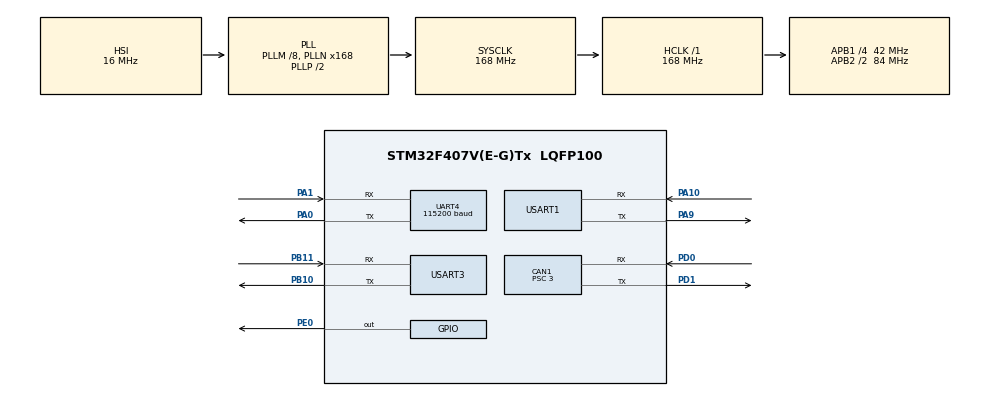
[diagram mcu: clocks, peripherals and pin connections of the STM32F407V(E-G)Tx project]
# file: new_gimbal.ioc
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CAN1.BS1=CAN_BS1_10TQ
CAN1.BS2=CAN_BS2_3TQ
CAN1.CalculateBaudRate=1000000
CAN1.CalculateTimeBit=999.99
CAN1.CalculateTimeQuantum=71.42857142857143
CAN1.Prescaler=3
FREERTOS.Tasks01=defaultTask,0,128,StartDefaultTask,Default,NULL,Dynamic,NULL,NULL;usart_,0,128,usart_task,As external,NULL,Dynamic,NULL,NULL;can_,0,128,can_task,As external,NULL,Dynamic,NULL,NULL
Mcu.Family=STM32F4
Mcu.Name=STM32F407V(E-G)Tx
Mcu.Package=LQFP100
NVIC.CAN1_RX0_IRQn=true\:5\:0\:false\:false\:true\:true\:true\:true
NVIC.PriorityGroup=NVIC_PRIORITYGROUP_4
NVIC.TIM1_UP_TIM10_IRQn=true\:0\:0\:false\:false\:true\:false\:false\:true
NVIC.TimeBase=TIM1_UP_TIM10_IRQn
NVIC.TimeBaseIP=TIM1
NVIC.UART4_IRQn=true\:5\:0\:false\:false\:false\:true\:true\:true
NVIC.USART1_IRQn=true\:5\:0\:false\:false\:true\:true\:true\:true
NVIC.USART3_IRQn=true\:5\:0\:false\:false\:false\:true\:true\:true
PA0-WKUP.Mode=Asynchronous
PA0-WKUP.Signal=UART4_TX
PA1.Mode=Asynchronous
PA1.Signal=UART4_RX
PA10.Mode=Asynchronous
PA10.Signal=USART1_RX
PA13.Mode=Serial_Wire
PA13.Signal=SYS_JTMS-SWDIO
PA14.Mode=Serial_Wire
PA14.Signal=SYS_JTCK-SWCLK
PA9.Mode=Asynchronous
PA9.Signal=USART1_TX
PB10.Mode=Asynchronous
PB10.Signal=USART3_TX
PB11.Mode=Asynchronous
PB11.Signal=USART3_RX
PD0.Mode=CAN_Activate
PD0.Signal=CAN1_RX
PD1.Mode=CAN_Activate
PD1.Signal=CAN1_TX
PE0.Signal=GPIO_Output
PH0-OSC_IN.Mode=HSE-External-Oscillator
PH0-OSC_IN.Signal=RCC_OSC_IN
PH1-OSC_OUT.Mode=HSE-External-Oscillator
PH1-OSC_OUT.Signal=RCC_OSC_OUT
ProjectManager.HeapSize=0x200
ProjectManager.StackSize=0x400
ProjectManager.TargetToolchain=MDK-ARM V5.27
RCC.48MHZClocksFreq_Value=84000000
RCC.AHBFreq_Value=168000000
RCC.APB1CLKDivider=RCC_HCLK_DIV4
RCC.APB1Freq_Value=42000000
RCC.APB1TimFreq_Value=84000000
RCC.APB2CLKDivider=RCC_HCLK_DIV2
RCC.APB2Freq_Value=84000000
RCC.APB2TimFreq_Value=168000000
RCC.CortexFreq_Value=168000000
RCC.HCLKFreq_Value=168000000
RCC.HSE_VALUE=12000000
RCC.HSI_VALUE=16000000
RCC.LSE_VALUE=32768
RCC.PLLM=8
RCC.PLLN=168
RCC.SYSCLKFreq_VALUE=168000000
RCC.SYSCLKSource=RCC_SYSCLKSOURCE_PLLCLK
RCC.VCOOutputFreq_Value=336000000
UART4.BaudRate=115200
UART4.VirtualMode=Asynchronous
USART1.VirtualMode=VM_ASYNC
USART3.VirtualMode=VM_ASYNC
VP_FREERTOS_VS_CMSIS_V1.Mode=CMSIS_V1
VP_SYS_VS_tim1.Mode=TIM1
board=custom

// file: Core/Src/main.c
/* USER CODE BEGIN Header */
/**
  ******************************************************************************
  * @file           : main.c
  * @brief          : Main program body
  ******************************************************************************
  * @attention
  *
  * <h2><center>&copy; Copyright (c) 2021 STMicroelectronics.
  * All rights reserved.</center></h2>
  *
  * This software component is licensed by ST under Ultimate Liberty license
  * SLA0044, the "License"; You may not use this file except in compliance with
  * the License. You may obtain a copy of the License at:
  *                             www.st.com/SLA0044
  *
  ******************************************************************************
  */
/* USER CODE END Header */
#include "main.h"
#include "cmsis_os.h"
#include "can.h"
#include "usart.h"
#include "gpio.h"

void SystemClock_Config(void);
void MX_FREERTOS_Init(void);

/* USER CODE BEGIN 0 */
extern uint8_t RxData[100];
uint8_t config_cmd[5]={0xff,0xaa,0x03,0x0c,0x00};
/* USER CODE END 0 */

int main(void)
{

  /* MCU Configuration--------------------------------------------------------*/

  /* Reset of all peripherals, Initializes the Flash interface and the Systick. */
  HAL_Init();

  /* Configure the system clock */
  SystemClock_Config();

  /* Initialize all configured peripherals */
  MX_GPIO_Init();
  MX_CAN1_Init();
  MX_UART4_Init();
  MX_USART3_UART_Init();
  MX_USART1_UART_Init();
  /* USER CODE BEGIN 2 */

  HAL_Delay(500);
//HAL_UART_Receive_IT(&huart1,RxData,1);
//HAL_Delay(5000);
//HAL_UART_Transmit(&huart4,config_cmd,5, 0xff);

HAL_GPIO_WritePin(GPIOE, GPIO_PIN_0,GPIO_PIN_SET);
  /* USER CODE END 2 */

  /* Call init function for freertos objects (in freertos.c) */
  MX_FREERTOS_Init();
  /* Start scheduler */
  osKernelStart();

  /* We should never get here as control is now taken by the scheduler */
  /* Infinite loop */
  while (1)
  {

  }
}

void SystemClock_Config(void)
{
  RCC_OscInitTypeDef RCC_OscInitStruct = {0};
  RCC_ClkInitTypeDef RCC_ClkInitStruct = {0};

  /** Configure the main internal regulator output voltage
  */
  __HAL_RCC_PWR_CLK_ENABLE();
  __HAL_PWR_VOLTAGESCALING_CONFIG(PWR_REGULATOR_VOLTAGE_SCALE1);
  /** Initializes the RCC Oscillators according to the specified parameters
  * in the RCC_OscInitTypeDef structure.
  */
  RCC_OscInitStruct.OscillatorType = RCC_OSCILLATORTYPE_HSI;
  RCC_OscInitStruct.HSIState = RCC_HSI_ON;
  RCC_OscInitStruct.HSICalibrationValue = RCC_HSICALIBRATION_DEFAULT;
  RCC_OscInitStruct.PLL.PLLState = RCC_PLL_ON;
  RCC_OscInitStruct.PLL.PLLSource = RCC_PLLSOURCE_HSI;
  RCC_OscInitStruct.PLL.PLLM = 8;
  RCC_OscInitStruct.PLL.PLLN = 168;
  RCC_OscInitStruct.PLL.PLLP = RCC_PLLP_DIV2;
  RCC_OscInitStruct.PLL.PLLQ = 4;
  if (HAL_RCC_OscConfig(&RCC_OscInitStruct) != HAL_OK)
  {
    Error_Handler();
  }
  /** Initializes the CPU, AHB and APB buses clocks
  */
  RCC_ClkInitStruct.ClockType = RCC_CLOCKTYPE_HCLK|RCC_CLOCKTYPE_SYSCLK
                              |RCC_CLOCKTYPE_PCLK1|RCC_CLOCKTYPE_PCLK2;
  RCC_ClkInitStruct.SYSCLKSource = RCC_SYSCLKSOURCE_PLLCLK;
  RCC_ClkInitStruct.AHBCLKDivider = RCC_SYSCLK_DIV1;
  RCC_ClkInitStruct.APB1CLKDivider = RCC_HCLK_DIV4;
  RCC_ClkInitStruct.APB2CLKDivider = RCC_HCLK_DIV2;

  if (HAL_RCC_ClockConfig(&RCC_ClkInitStruct, FLASH_LATENCY_5) != HAL_OK)
  {
    Error_Handler();
  }
}

 /**
  * @brief  Period elapsed callback in non blocking mode
  * @note   This function is called  when TIM1 interrupt took place, inside
  * HAL_TIM_IRQHandler(). It makes a direct call to HAL_IncTick() to increment
  * a global variable "uwTick" used as application time base.
  * @param  htim : TIM handle
  * @retval None
  */
void HAL_TIM_PeriodElapsedCallback(TIM_HandleTypeDef *htim)
{
  if (htim->Instance == TIM1) {
    HAL_IncTick();
  }
}

void Error_Handler(void)
{
  __disable_irq();
  while (1)
  {
  }
}

/************************ (C) COPYRIGHT STMicroelectronics *****END OF FILE****/

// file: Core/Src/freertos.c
/* USER CODE BEGIN Header */
/**
  ******************************************************************************
  * File Name          : freertos.c
  * Description        : Code for freertos applications
  ******************************************************************************
  * @attention
  *
  * <h2><center>&copy; Copyright (c) 2021 STMicroelectronics.
  * All rights reserved.</center></h2>
  *
  * This software component is licensed by ST under Ultimate Liberty license
  * SLA0044, the "License"; You may not use this file except in compliance with
  * the License. You may obtain a copy of the License at:
  *                             www.st.com/SLA0044
  *
  ******************************************************************************
  */
/* USER CODE END Header */

#include "FreeRTOS.h"
#include "task.h"
#include "main.h"
#include "cmsis_os.h"

/* USER CODE BEGIN Includes */
#include "usart_task.h"
#include "can_task.h"
/* USER CODE END Includes */

osThreadId defaultTaskHandle;
osThreadId usart_Handle;
osThreadId can_Handle;

void StartDefaultTask(void const * argument);
extern void usart_task(void const * argument);
extern void can_task(void const * argument);

void MX_FREERTOS_Init(void); /* (MISRA C 2004 rule 8.1) */

/* GetIdleTaskMemory prototype (linked to static allocation support) */
void vApplicationGetIdleTaskMemory( StaticTask_t **ppxIdleTaskTCBBuffer, StackType_t **ppxIdleTaskStackBuffer, uint32_t *pulIdleTaskStackSize );

/* USER CODE BEGIN GET_IDLE_TASK_MEMORY */
static StaticTask_t xIdleTaskTCBBuffer;
static StackType_t xIdleStack[configMINIMAL_STACK_SIZE];

void vApplicationGetIdleTaskMemory( StaticTask_t **ppxIdleTaskTCBBuffer, StackType_t **ppxIdleTaskStackBuffer, uint32_t *pulIdleTaskStackSize )
{
  *ppxIdleTaskTCBBuffer = &xIdleTaskTCBBuffer;
  *ppxIdleTaskStackBuffer = &xIdleStack[0];
  *pulIdleTaskStackSize = configMINIMAL_STACK_SIZE;
  /* place for user code */
}
/* USER CODE END GET_IDLE_TASK_MEMORY */

void MX_FREERTOS_Init(void) {

  /* Create the thread(s) */
  /* definition and creation of defaultTask */
  osThreadDef(defaultTask, StartDefaultTask, osPriorityNormal, 0, 128);
  defaultTaskHandle = osThreadCreate(osThread(defaultTask), NULL);

  /* definition and creation of usart_ */
  osThreadDef(usart_, usart_task, osPriorityNormal, 0, 128);
  usart_Handle = osThreadCreate(osThread(usart_), NULL);

  /* definition and creation of can_ */
  osThreadDef(can_, can_task, osPriorityNormal, 0, 128);
  can_Handle = osThreadCreate(osThread(can_), NULL);

}

void StartDefaultTask(void const * argument)
{
  for(;;)
  {
    osDelay(1);
  }
}

/************************ (C) COPYRIGHT STMicroelectronics *****END OF FILE****/
